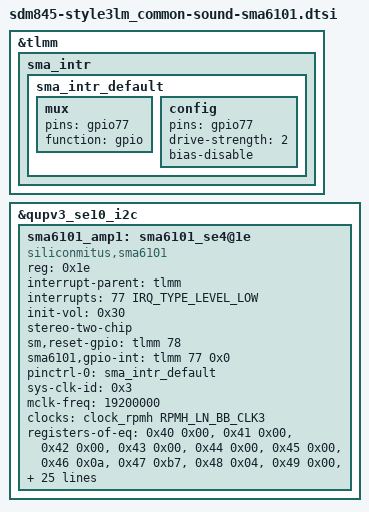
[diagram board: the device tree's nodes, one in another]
/* Copyright (c) 2017, The Linux Foundation. All rights reserved.
 *
 * This program is free software; you can redistribute it and/or modify
 * it under the terms of the GNU General Public License version 2 and
 * only version 2 as published by the Free Software Foundation.
 *
 * This program is distributed in the hope that it will be useful,
 * but WITHOUT ANY WARRANTY; without even the implied warranty of
 * MERCHANTABILITY or FITNESS FOR A PARTICULAR PURPOSE.  See the
 * GNU General Public License for more details.
 */

&tlmm {
	sma_intr {
		sma_intr_default: sma_intr_default {
			mux {
				pins = "gpio77";
				function = "gpio";
			};

			config {
				pins = "gpio77";
				drive-strength = <2>; /* 2 mA */
				bias-disable;  /* NO pull */
			};
		};
	};
};

&qupv3_se10_i2c{ /* QUPV3 SE10  */
	sma6101_amp1: sma6101_se4@1e {
		compatible = "siliconmitus,sma6101";
		reg = <0x1e>;
		interrupt-parent = <&tlmm>;
		interrupts = <77 IRQ_TYPE_LEVEL_LOW>;

		init-vol = <0x30>;
		stereo-two-chip;
		sm,reset-gpio = <&tlmm 78 0x0>;

		/* SRC-bypass; */

		/* registers-of-amp = <0x0e 0xae>,<0x14 0x18>,<0x19 0x20>,<0x37 0x10>,<0x3c 0x30>,
				   <0x97 0xec>,
				   <0x23 0x95>,<0x24 0x0>,<0x25 0x0>,<0x26 0x78>; */
		sma6101,gpio-int= <&tlmm 77 0x0>;

		pinctrl-names = "default";
		pinctrl-0 = <&sma_intr_default>;

		sys-clk-id = <0x3>;
		mclk-freq = <19200000>;
		/* to use ln_bb_clk3 as MCLK in SMA6101 */
		/* sys-clk-id = <0x2> */
		/* enable SMA6101_MCLK in pm_pvc_config.c refer to lamp_p_release_sm8150*/
		clock-names = "ln_bb_clk3";
		clocks = <&clock_rpmh RPMH_LN_BB_CLK3>;

		registers-of-eq = <0x40 0x00>,<0x41 0x00>,
				  <0x42 0x00>,<0x43 0x00>,
				  <0x44 0x00>,<0x45 0x00>,
				  <0x46 0x0a>,<0x47 0xb7>,
				  <0x48 0x04>,<0x49 0x00>,
				  <0x4a 0x00>,<0x4b 0x00>,
				  <0x4c 0x35>,<0x4d 0x48>,
				  <0x4e 0x03>,<0x4f 0x24>,
				  <0x50 0x85>,<0x51 0x06>,
				  <0x52 0xa3>,<0x53 0x21>,
				  <0x54 0x01>,<0x55 0x40>,
				  <0x56 0x00>,<0x57 0x00>,
				  <0x58 0xdb>,<0x59 0x7a>,
				  <0x5a 0x02>,<0x5b 0x5c>,
				  <0x5c 0xde>,<0x5d 0x07>,
				  <0x5e 0x3b>,<0x5f 0xc3>,
				  <0x60 0x06>,<0x61 0x85>,
				  <0x62 0x26>,<0x63 0x03>,
				  <0x64 0x40>,<0x65 0x3e>,
				  <0x66 0x02>,<0x67 0xc3>,
				  <0x68 0xfd>,<0x69 0x06>,
				  <0x6a 0x7a>,<0x6b 0xd9>,
				  <0x6c 0x05>,<0x6d 0x0a>,
				  <0x6e 0xef>,<0x6f 0x00>,
				  <0x70 0x09>,<0x71 0xc7>,
				  <0x72 0x07>,<0x73 0x40>,
				  <0x74 0x00>,<0x75 0x00>,
				  <0x76 0xf5>,<0x77 0x11>,
				  <0x78 0x00>,<0x79 0xf6>,
				  <0x7a 0x38>,<0x7b 0x01>,
				  <0x7c 0x28>,<0x7d 0x88>,
				  <0x7e 0x03>,<0x7f 0xaa>,
				  <0x80 0xef>,<0x81 0x02>,
				  <0x82 0x42>,<0x83 0xb0>,
				  <0x84 0x04>,<0x85 0xd4>,
				  <0x86 0xc7>,<0x87 0x00>,
				  <0x88 0x55>,<0x89 0x10>,
				  <0x8a 0x06>;
		registers-of-bo = <0x05 0xb8>,<0x06 0x38>,
				  <0x07 0x38>,<0x08 0x38>,
				  <0x0b 0x38>,<0x0c 0x38>,
				  <0x38 0x00>,<0x39 0x8c>,
				  <0x3a 0xcc>,<0xb0 0x85>,
				  <0xb1 0x8e>,<0xb2 0x89>,
				  <0xb3 0x7f>,<0xb4 0x1b>,
				  <0xb5 0x1a>,<0xb6 0x48>,
				  <0xb7 0x40>,<0xb8 0x77>,
				  <0xb9 0x76>,<0xba 0x75>,
				  <0xbb 0x6f>,<0xbc 0x19>,
				  <0xbd 0x18>,<0xbe 0x17>,
				  <0xbf 0x17>,<0x1c 0x3b>,
				  <0x1d 0x2d>,<0x1e 0x2d>,
				  <0x1f 0x2d>,<0x20 0x0f>;

		status = "ok";
	};
};

